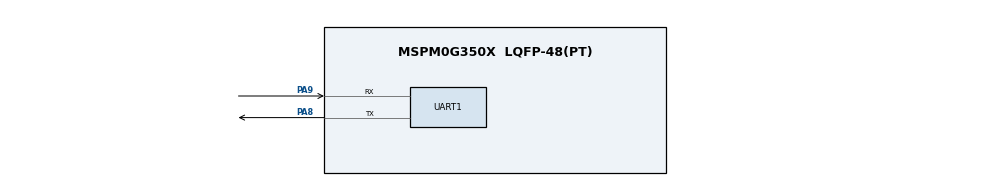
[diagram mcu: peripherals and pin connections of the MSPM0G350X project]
/**
 *
 * @cliArgs --device "MSPM0G350X" --part "Default" --package "LQFP-48(PT)" --product "mspm0_sdk@2.11.00.07"
 * @versions {"tool":"1.28.0+4712"}
 */

/**
 * Import the modules used in this configuration.
 */
const ADC12  = scripting.addModule("/ti/driverlib/ADC12", {}, false);
const ADC121 = ADC12.addInstance();
const UART   = scripting.addModule("/ti/driverlib/UART", {}, false);
const UART1  = UART.addInstance();

/**
 * Write custom configuration values to the imported modules.
 */
ADC121.$name          = "ADC12_0";
ADC121.sampClkSrc     = "DL_ADC12_CLOCK_ULPCLK";
ADC121.sampClkDiv     = "DL_ADC12_CLOCK_DIVIDE_8";
ADC121.adcMem0chansel = "DL_ADC12_INPUT_CHAN_0";
ADC121.sampleTime0    = "125 us";
ADC121.powerDownMode  = "DL_ADC12_POWER_DOWN_MODE_MANUAL";

UART1.$name                            = "HC05_UART";
UART1.targetBaudRate                   = 115200;
UART1.peripheral.rxPin.$assign         = "PA9";
UART1.peripheral.txPin.$assign         = "PA8";
UART1.txPinConfig.$name                = "ti_driverlib_gpio_GPIOPinGeneric1";
UART1.txPinConfig.direction            = scripting.forceWrite("OUTPUT");
UART1.txPinConfig.hideOutputInversion  = scripting.forceWrite(false);
UART1.txPinConfig.onlyInternalResistor = scripting.forceWrite(false);
UART1.txPinConfig.passedPeripheralType = scripting.forceWrite("Digital");
UART1.rxPinConfig.$name                = "ti_driverlib_gpio_GPIOPinGeneric2";
UART1.rxPinConfig.hideOutputInversion  = scripting.forceWrite(false);
UART1.rxPinConfig.onlyInternalResistor = scripting.forceWrite(false);
UART1.rxPinConfig.passedPeripheralType = scripting.forceWrite("Digital");

const Board = scripting.addModule("/ti/driverlib/Board", {}, false);

const SYSCTL = scripting.addModule("/ti/driverlib/SYSCTL", {}, false);

/**
 * Pinmux solution for unlocked pins/peripherals. This ensures that minor changes to the automatic solver in a future
 * version of the tool will not impact the pinmux you originally saw.  These lines can be completely deleted in order to
 * re-solve from scratch.
 */
ADC121.peripheral.$suggestSolution         = "ADC0";
ADC121.peripheral.adcPin0.$suggestSolution = "PA27";
UART1.peripheral.$suggestSolution          = "UART1";
Board.peripheral.$suggestSolution          = "DEBUGSS";
Board.peripheral.swclkPin.$suggestSolution = "PA20";
Board.peripheral.swdioPin.$suggestSolution = "PA19";
SYSCTL.peripheral.$suggestSolution         = "SYSCTL";
